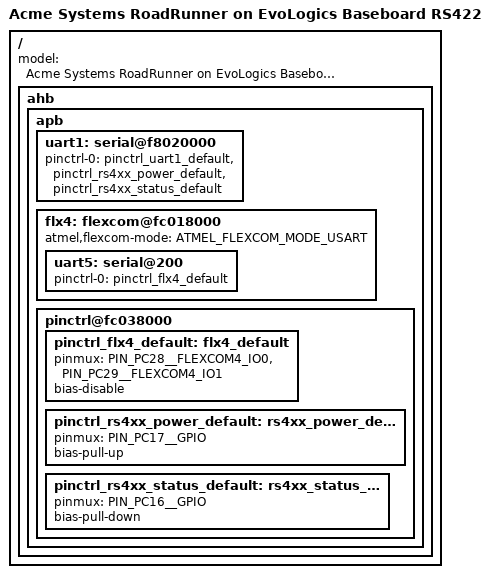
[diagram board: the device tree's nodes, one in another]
/dts-v1/;
#include "sama5d2-roadrunner-evomini2.dtsi"

/ {
    model = "Acme Systems RoadRunner on EvoLogics Baseboard RS422";

	ahb {
		apb {
			uart1: serial@f8020000 {
				pinctrl-names = "default";
				/* pinctrl-0 = <&pinctrl_uart1_default>; */
				pinctrl-0 = <&pinctrl_uart1_default
                             &pinctrl_rs4xx_power_default
                             &pinctrl_rs4xx_status_default>;
				status = "okay";
			};

			flx4: flexcom@fc018000 {
				atmel,flexcom-mode = <ATMEL_FLEXCOM_MODE_USART>;
				status = "okay";

				uart5: serial@200 {
                    pinctrl-names = "default";
					pinctrl-0 = <&pinctrl_flx4_default>;
					status = "okay";
				};
			};

			pinctrl@fc038000 {
				pinctrl_flx4_default: flx4_default {
					pinmux = <PIN_PC28__FLEXCOM4_IO0>,
                             <PIN_PC29__FLEXCOM4_IO1>;
					bias-disable;
				};

                pinctrl_rs4xx_power_default: rs4xx_power_default {
                    pinmux  = <PIN_PC17__GPIO>;
                    bias-pull-up;
                };

                pinctrl_rs4xx_status_default: rs4xx_status_default {
                    pinmux  = <PIN_PC16__GPIO>;
                    bias-pull-down;
                };
          };
	  };
   };
};
